# WKUP_CBASS0_GLB register map
Vendor: Texas Instruments
Peripheral module from a debugger description file (folder am65x).
Registers are 32-bit, read-only, reset values left out (the file's numbers can be read two ways) unless marked. A register's access mark holds for its fields unless they carry their own. Offsets are as the file gives them; lines under a group give offsets from that group; [hi:lo] are bit positions; {n}, {i} and the like mark numbered series; 'fields as' and 'values as' point back to an identical list; <NAME> marks a mode.

## WKUP_CBASS0_GLB
0x00 CBA_PID — The Revision Register contains the major and minor revisions for the module.
  [31:0] REV — TI internal data.
0x04 CBA_DESTINATION_ID rw — The Destination ID Register defines the destination ID value for error messages.
  [7:0] DEST_ID — The destination ID.
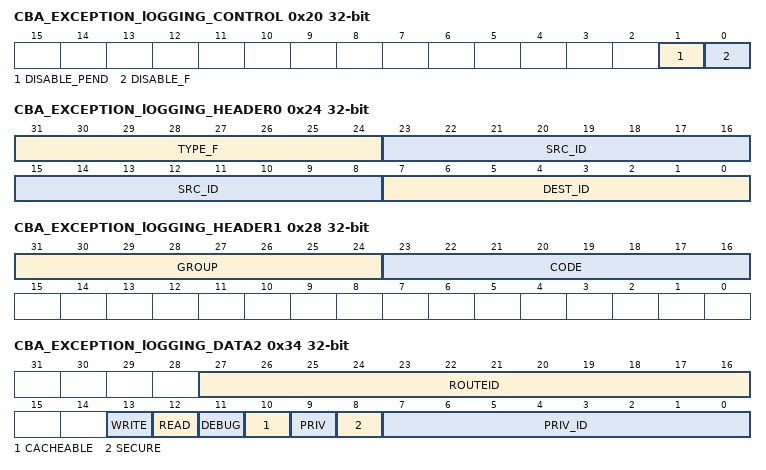
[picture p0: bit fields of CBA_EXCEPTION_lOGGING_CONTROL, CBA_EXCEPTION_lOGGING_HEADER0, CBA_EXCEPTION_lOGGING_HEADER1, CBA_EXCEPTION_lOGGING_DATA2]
0x20 CBA_EXCEPTION_lOGGING_CONTROL rw — The Exception Logging Control Register controls the exception logging.
  [1] DISABLE_PEND — Disables logging pending when set.
  [0] DISABLE_F — Disables logging when set.
0x24 CBA_EXCEPTION_lOGGING_HEADER0 — The Exception Logging Header 0 Register contains the first word of the header.
  [31:24] TYPE_F — Type.
  [23:8] SRC_ID — Source ID.
  [7:0] DEST_ID — Destination ID.
0x28 CBA_EXCEPTION_lOGGING_HEADER1 — The Exception Logging Header 1 Register contains the second word of the header.
  [31:24] GROUP, [23:16] CODE
0x2C CBA_EXCEPTION_lOGGING_DATA0 — The Exception Logging Data 0 Register contains the first word of the data.
  [31:0] ADDR_L — Address lower 32 bits.
0x30 CBA_EXCEPTION_lOGGING_DATA1 — The Exception Logging Data 1 Register contains the second word of the data.
  [15:0] ADDR_H — Address upper 16 bits.
0x34 CBA_EXCEPTION_lOGGING_DATA2 — The Exception Logging Data 2 Register contains the third word of the data.
  [27:16] ROUTEID, [13] WRITE, [12] READ, [11] DEBUG, [10] CACHEABLE, [9] PRIV, [8] SECURE, [7:0] PRIV_ID
0x38 CBA_EXCEPTION_lOGGING_DATA3 — The Exception Logging Data 3 Register contains the fourth word of the data.
  [9:0] BYTECNT — Byte count.
0x40 CBA_EXCEPTION_PEND_SET rw — The Exception Logging Pending Set Register allows to set the pend signal.
  [0] PEND_SET — Write a 1 to set the exception pend signal.
0x44 CBA_EXCEPTION_PEND_CLEAR rw — The Exception Logging Pending Clear Register allows to clear the pend signal.
  [0] PEND_CLR — Write a 1 to clear the exception pend signal.
